# STM32MP153 register map
File version: 1.3
CPU: CM4 r0p1, little endian, no MPU, FPU, 4 interrupt priority bits
Registers are 32-bit, read-write, reset 0x0 unless marked. A register's access mark holds for its fields unless they carry their own. Offsets are from the block's base; [hi:lo] are bit positions; lines under a group give offsets from that group; {n}, {i} and the like mark numbered series; 'fields as' and 'values as' point back to an identical list.

## ETH_MAC_MMC
Base 0x5800A000
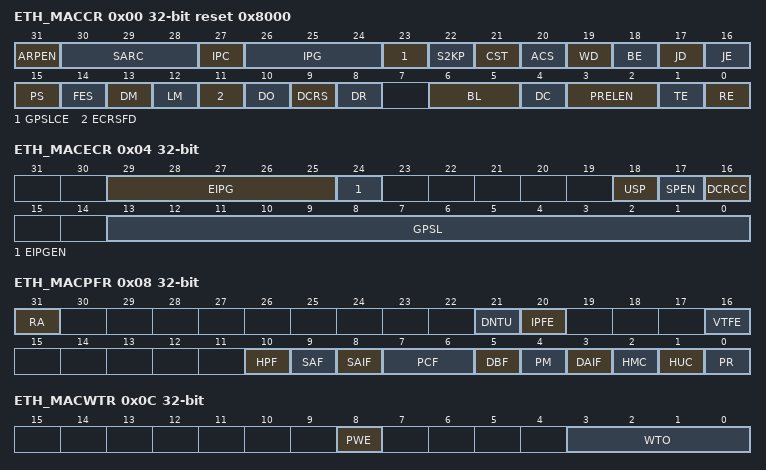
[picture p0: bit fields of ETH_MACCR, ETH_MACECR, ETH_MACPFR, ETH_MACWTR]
0x00 ETH_MACCR reset 0x8000 — The MAC Configuration Register establishes the operating mode of the MAC.
  [31] ARPEN, [30:28] SARC, [27] IPC, [26:24] IPG, [23] GPSLCE, [22] S2KP, [21] CST, [20] ACS, [19] WD, [18] BE, [17] JD, [16] JE, [15] PS, [14] FES, [13] DM, [12] LM, [11] ECRSFD, [10] DO, [9] DCRS, [8] DR, [6:5] BL, [4] DC, [3:2] PRELEN, [1] TE, [0] RE
0x04 ETH_MACECR — The MAC Extended Configuration Register establishes the operating mode of the MAC.
  [29:25] EIPG, [24] EIPGEN, [18] USP, [17] SPEN, [16] DCRCC, [13:0] GPSL
0x08 ETH_MACPFR — The MAC Packet Filter register contains the filter controls for receiving packets. Some of the controls from this register go to the address check block of the MAC which performs the first level of address filtering. The second level of filtering is performed on the incoming packet based on other controls such as Pass Bad Packets and Pass Control Packets.
  [31] RA, [21] DNTU, [20] IPFE, [16] VTFE, [10] HPF, [9] SAF, [8] SAIF, [7:6] PCF, [5] DBF, [4] PM, [3] DAIF, [2] HMC, [1] HUC, [0] PR
0x0C ETH_MACWTR — The Watchdog Timeout register controls the watchdog timeout for received packets.
  [8] PWE, [3:0] WTO
0x10 ETH_MACHT0R — The Hash Table Register 0 contains the first 32 bits of the Hash table (64 bits). For Hash filtering, the content of the destination address in the incoming packet is passed through the CRC logic and the upper six bits of the CRC register are used to index the content of the Hash table. The most significant bits determines the register to be used (Hash Table Register 0 or 1). The Hash value of the destination address is calculated in the following way: Calculate the 32-bit CRC for the DA (See IEEE 802.3, Section 3.2.8 for the steps to calculate CRC32). Perform bitwise reversal for the value obtained in Step 1. Take the upper 7 or 8 bits from the value obtained in Step 2. If the corresponding bit value of the register is 1, the packet is accepted. Otherwise, it is rejected. If the PM bit is set in ETH_MACPFR, all multicast packets are accepted regardless of the multicast Hash values. If the Hash Table register is configured to be double-synchronized to the GMII clock domain, the synchronization is triggered only when Bits[31:24] (in little-endian mode) or Bits[7:0] (in big-endian mode) of the Hash Table Register X registers are written.
  [31:0] HT31T0
0x14 ETH_MACHT1R — The Hash Table Register 1contains the last 32 bits of the Hash table (64 bits). For Hash filtering, the content of the destination address in the incoming packet is passed through the CRC logic and the upper six bits of the CRC register are used to index the content of the Hash table. The most significant bits determines the register to be used (Hash Table Register 0 or 1). The Hash value of the destination address is calculated in the following way: Calculate the 32-bit CRC for the DA (See IEEE 802.3, Section 3.2.8 for the steps to calculate CRC32). Perform bitwise reversal for the value obtained in Step 1. Take the upper 7 or 8 bits from the value obtained in Step 2. If the corresponding bit value of the register is 1, the packet is accepted. Otherwise, it is rejected. If the PM bit is set in ETH_MACPFR, all multicast packets are accepted regardless of the multicast Hash values. If the Hash Table register is configured to be double-synchronized to the GMII clock domain, the synchronization is triggered only when Bits[31:24] (in little-endian mode) or Bits[7:0] (in big-endian mode) of the Hash Table Register X registers are written.
  [31:0] HT63T32
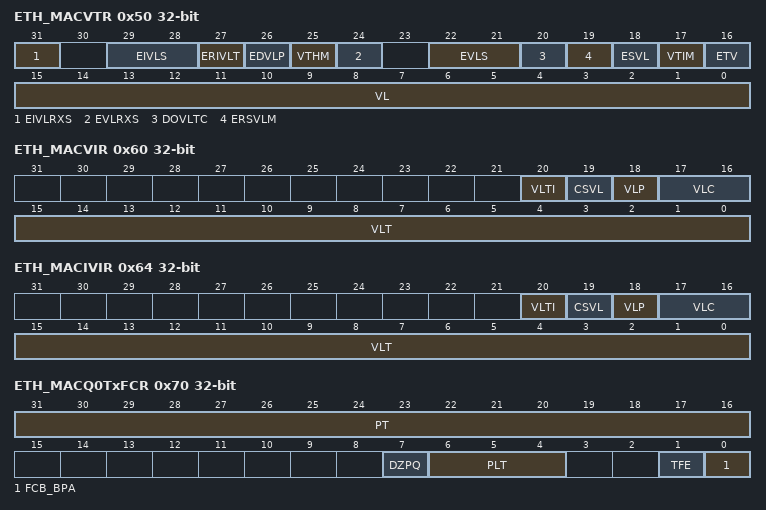
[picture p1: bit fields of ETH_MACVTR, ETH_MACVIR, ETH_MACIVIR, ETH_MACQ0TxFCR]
0x50 ETH_MACVTR — The VLAN Tag register identifies the IEEE 802.1Q VLAN type packets.
  [31] EIVLRXS, [29:28] EIVLS, [27] ERIVLT, [26] EDVLP, [25] VTHM, [24] EVLRXS, [22:21] EVLS, [20] DOVLTC, [19] ERSVLM, [18] ESVL, [17] VTIM, [16] ETV, [15:0] VL
0x58 ETH_MACVHTR — When the ERSVLM bit of ETH_MACHT1R register is set, the 16-bit VLAN Hash Table register is used for group address filtering based on the VLAN tag. For Hash filtering, the content of the 16-bit VLAN tag or 12-bit VLAN ID (based on the ETV bit of ETH_MACVTR register) in the incoming packet is passed through the CRC logic. The upper four bits of the calculated CRC are used to index the contents of the VLAN Hash table. For example, a Hash value of 1000 selects Bit 8 of the VLAN Hash table. The Hash value of the destination address is calculated in the following way: Calculate the 32-bit CRC for the VLAN tag or ID (For steps to calculate CRC32, see Section 3.2.8 of IEEE 802.3). Perform bitwise reversal for the value obtained in step 1. Take the upper four bits from the value obtained in step 2. If the VLAN Hash Table register is configured to be double-synchronized to the GMII clock domain, the synchronization is triggered only when Bits[15:8] (in little-endian mode) or Bits[7:0] (in big-endian mode) of this register are written.
  [15:0] VLHT
0x60 ETH_MACVIR — The VLAN Tag Inclusion or Replacement register contains the VLAN tag for insertion or replacement in the Transmit packets. It also contains the VLAN tag insertion controls.
  [20] VLTI, [19] CSVL, [18] VLP, [17:16] VLC, [15:0] VLT
0x64 ETH_MACIVIR — The Inner VLAN Tag Inclusion or Replacement register contains the inner VLAN tag to be inserted or replaced in the Transmit packet. It also contains the inner VLAN tag insertion controls.
  [20] VLTI, [19] CSVL, [18] VLP, [17:16] VLC, [15:0] VLT
0x70 ETH_MACQ0TxFCR — The Flow Control register controls the generation and reception of the Control (Pause Command) packets by the Flow control module of the MAC. A Write to a register with the Busy bit set to 1 triggers the Flow Control block to generate a Pause packet. The fields of the control packet are selected as specified in the 802.3x specification, and the Pause Time value from this register is used in the Pause Time field of the control packet. The Busy bit remains set until the control packet is transferred onto the cable. The application must make sure that the Busy bit is cleared before writing to the register.
  [31:16] PT, [7] DZPQ, [6:4] PLT, [1] TFE, [0] FCB_BPA
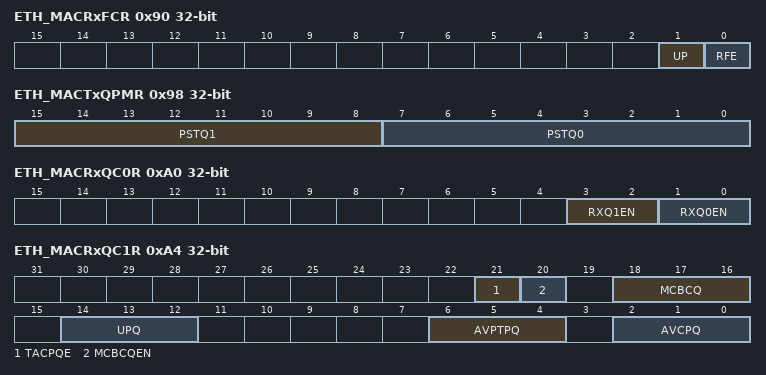
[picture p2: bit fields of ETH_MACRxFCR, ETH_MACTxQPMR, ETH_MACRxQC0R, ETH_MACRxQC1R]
0x90 ETH_MACRxFCR — The Receive Flow Control register controls the pausing of MAC Transmit based on the received Pause packet.
  [1] UP, [0] RFE
0x98 ETH_MACTxQPMR ro — The transmit queue priority mapping 0 register contains the priority values assigned to Tx queue 0 and tx queue 1.
  [15:8] PSTQ1, [7:0] PSTQ0
0xA0 ETH_MACRxQC0R — The Receive Queue Control 0 register controls the queue management in the MAC Receiver.
  [3:2] RXQ1EN, [1:0] RXQ0EN
0xA4 ETH_MACRxQC1R — The Receive Queue Control 1 register controls queue 1 management in the MAC receiver.
  [21] TACPQE, [20] MCBCQEN, [18:16] MCBCQ, [14:12] UPQ, [6:4] AVPTPQ, [2:0] AVCPQ
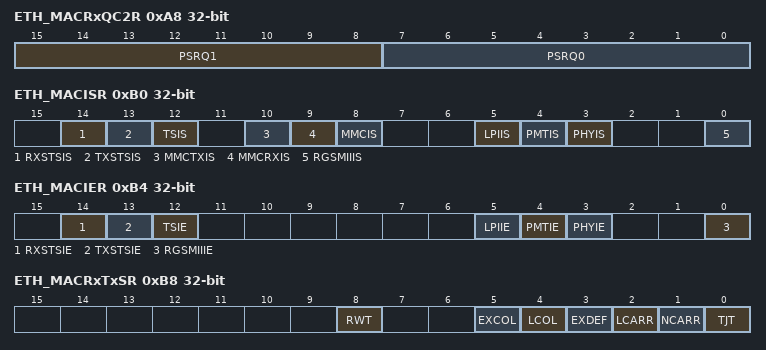
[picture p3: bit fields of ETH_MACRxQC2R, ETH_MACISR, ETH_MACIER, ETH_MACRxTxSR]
0xA8 ETH_MACRxQC2R — This register controls the routing of tagged packets based on the USP (user priority) field of the received packets to the Rx queue 0 and 1.
  [15:8] PSRQ1, [7:0] PSRQ0
0xB0 ETH_MACISR ro — The Interrupt Status register contains the status of interrupts.
  [14] RXSTSIS, [13] TXSTSIS, [12] TSIS, [10] MMCTXIS, [9] MMCRXIS, [8] MMCIS, [5] LPIIS, [4] PMTIS, [3] PHYIS, [0] RGSMIIIS
0xB4 ETH_MACIER — The Interrupt Enable register contains the masks for generating the interrupts.
  [14] RXSTSIE, [13] TXSTSIE, [12] TSIE, [5] LPIIE, [4] PMTIE, [3] PHYIE, [0] RGSMIIIE
0xB8 ETH_MACRxTxSR ro — The Receive Transmit Status register contains the Receive and Transmit Error status.
  [8] RWT, [5] EXCOL, [4] LCOL, [3] EXDEF, [2] LCARR, [1] NCARR, [0] TJT
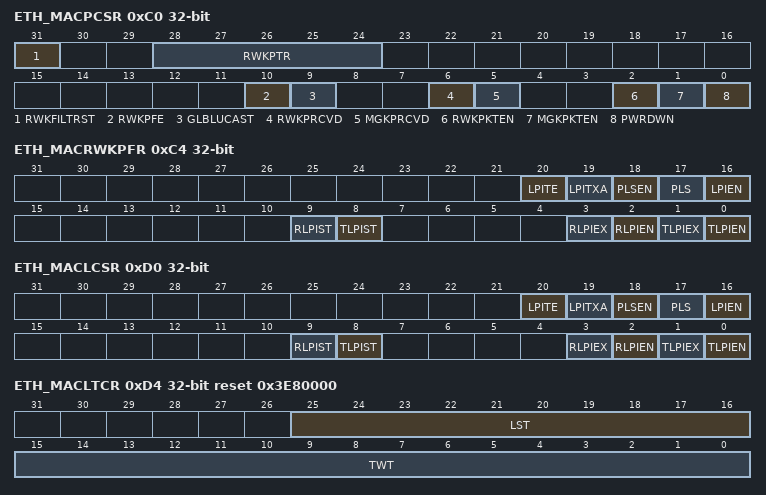
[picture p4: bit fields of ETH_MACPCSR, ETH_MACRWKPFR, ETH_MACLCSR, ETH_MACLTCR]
0xC0 ETH_MACPCSR — The PMT Control and Status Register is present only when you select the PMT module in coreConsultant.
  [31] RWKFILTRST, [28:24] RWKPTR ro, [10] RWKPFE, [9] GLBLUCAST, [6] RWKPRCVD ro, [5] MGKPRCVD ro, [2] RWKPKTEN, [1] MGKPKTEN, [0] PWRDWN
0xC4 ETH_MACRWKPFR — The LPI Control and Status Register controls the LPI functions and provides the LPI interrupt status. The status bits are cleared when this register is read.
  [20] LPITE, [19] LPITXA, [18] PLSEN, [17] PLS, [16] LPIEN, [9] RLPIST ro, [8] TLPIST ro, [3] RLPIEX ro, [2] RLPIEN ro, [1] TLPIEX ro, [0] TLPIEN ro
0xD0 ETH_MACLCSR — The LPI Control and Status Register controls the LPI functions and provides the LPI interrupt status. The status bits are cleared when this register is read.
  fields as ETH_MACRWKPFR
0xD4 ETH_MACLTCR reset 0x3E80000 — The LPI Timers Control register controls the timeout values in the LPI states. It specifies the time for which the MAC transmits the LPI pattern and also the time for which the MAC waits before resuming the normal transmission.
  [25:16] LST, [15:0] TWT
0xD8 ETH_MACLETR — The LPI Entry Timer Register is used to store the LPI Idle Timer Value in Micro-Seconds.
  [19:3] LPIET
0xDC ETH_MAC1USTCR — This register controls the generation of the Reference time (1-microsecond tick) for all the LPI timers. This timer has to be programmed by the software initially.
  [11:0] TIC_1US_CNTR
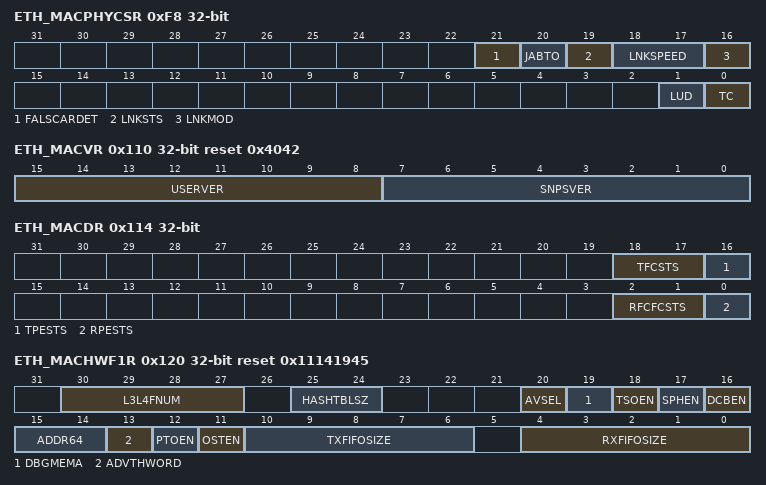
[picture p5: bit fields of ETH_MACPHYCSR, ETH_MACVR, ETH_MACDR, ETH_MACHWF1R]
0xF8 ETH_MACPHYCSR — The PHY Interface Control and Status register indicates the status signals received by the, RGMII interface from the PHY.
  [21] FALSCARDET ro, [20] JABTO ro, [19] LNKSTS ro, [18:17] LNKSPEED ro, [16] LNKMOD ro, [1] LUD, [0] TC
0x110 ETH_MACVR ro reset 0x4042 — The version register identifies the version of the Ethernet peripheral.
  [15:8] USERVER, [7:0] SNPSVER
0x114 ETH_MACDR ro — The Debug register provides the debug status of various MAC blocks.
  [18:17] TFCSTS, [16] TPESTS, [2:1] RFCFCSTS, [0] RPESTS
0x120 ETH_MACHWF1R ro reset 0x11141945 — This register indicates the presence of second set of the optional features or functions of the Ethernet peripheral. The software driver can use this register to dynamically enable or disable the programs related to the optional blocks.
  [30:27] L3L4FNUM, [25:24] HASHTBLSZ, [20] AVSEL, [19] DBGMEMA, [18] TSOEN, [17] SPHEN, [16] DCBEN, [15:14] ADDR64, [13] ADVTHWORD, [12] PTOEN, [11] OSTEN, [10:6] TXFIFOSIZE, [4:0] RXFIFOSIZE
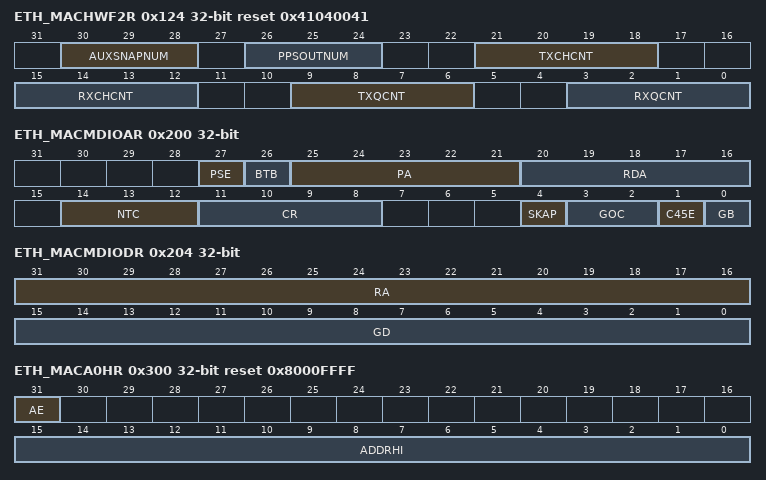
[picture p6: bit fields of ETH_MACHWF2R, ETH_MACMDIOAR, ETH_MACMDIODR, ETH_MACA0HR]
0x124 ETH_MACHWF2R ro reset 0x41040041 — This register indicates the presence of third set of the optional features or functions of the Ethernet peripheral. The software driver can use this register to dynamically enable or disable the programs related to the optional blocks.
  [30:28] AUXSNAPNUM, [26:24] PPSOUTNUM, [21:18] TXCHCNT, [15:12] RXCHCNT, [9:6] TXQCNT, [3:0] RXQCNT
0x200 ETH_MACMDIOAR — The MDIO Address register controls the management cycles to external PHY through a management interface.
  [27] PSE, [26] BTB, [25:21] PA, [20:16] RDA, [14:12] NTC, [11:8] CR, [4] SKAP, [3:2] GOC, [1] C45E, [0] GB
0x204 ETH_MACMDIODR — The MDIO Data register stores the Write data to be written to the PHY register located at the address specified in ETH_MACMDIOAR. This register also stores the Read data from the PHY register located at the address specified by MDIO Address register.
  [31:16] RA, [15:0] GD
0x300 ETH_MACA0HR reset 0x8000FFFF — The MAC Address0 High register holds the upper 16 bits of the first 6-byte MAC address of the station. The first DA byte that is received on the GMII interface corresponds to the LS byte (Bits [7:0]) of the MAC Address Low register. For example, if 0x112233445566 is received (0x11 in lane 0 of the first column) on the GMII as the destination address, then the MacAddress0 Register [47:0] is compared with 0x665544332211. If the MAC address registers are configured to be double-synchronized to the GMII clock domains, then the synchronization is triggered only when Bits[31:24] (in little-endian mode) or Bits[7:0] (in big-endian mode) of the MAC Address0 Low Register are written. For proper synchronization updates, the consecutive writes to this Address Low Register should be performed after at least four clock cycles in the destination clock domain.
  [31] AE ro, [15:0] ADDRHI
{0x304+8i} ETH_MACA{i}LR reset 0xFFFFFFFF (i=0..3) — The MAC Address x Low register holds the lower 32 bits of the 6-byte first MAC address of the station.
  [31:0] ADDRLO
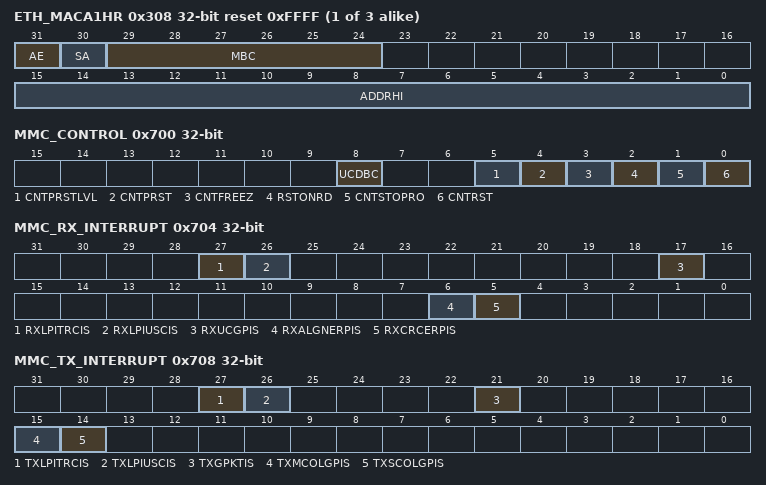
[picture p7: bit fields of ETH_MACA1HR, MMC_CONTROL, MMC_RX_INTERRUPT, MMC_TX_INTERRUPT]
{0x300+8i} ETH_MACA{i}HR reset 0xFFFF (i=1..3) — The MAC Address x High register holds the upper 16 bits of the second 6-byte MAC address of the station.
  [31] AE, [30] SA, [29:24] MBC, [15:0] ADDRHI
0x700 MMC_CONTROL — This register configures the MMC operating mode.
  [8] UCDBC, [5] CNTPRSTLVL, [4] CNTPRST, [3] CNTFREEZ, [2] RSTONRD, [1] CNTSTOPRO, [0] CNTRST
0x704 MMC_RX_INTERRUPT ro — This register maintains the interrupts generated from all Receive statistics counters. The MMC Receive Interrupt register maintains the interrupts that are generated when the following occur: Receive statistic counters reach half of their maximum values (0x8000_0000 for 32 bit counter and 0x8000 for 16 bit counter). Receive statistic counters cross their maximum values (0xFFFF_FFFF for 32 bit counter and 0xFFFF for 16 bit counter). When the Counter Stop Rollover is set, interrupts are set but the counter remains at all-ones. The MMC Receive Interrupt register is a 32 bit register. An interrupt bit is cleared when the respective MMC counter that caused the interrupt is read. The least significant byte lane (Bits[7:0]) of the respective counter must be read to clear the interrupt bit.
  [27] RXLPITRCIS, [26] RXLPIUSCIS, [17] RXUCGPIS, [6] RXALGNERPIS, [5] RXCRCERPIS
0x708 MMC_TX_INTERRUPT ro — This register maintains the interrupts generated from all Transmit statistics counters. The MMC Transmit Interrupt register maintains the interrupts generated when transmit statistic counters reach half their maximum values (0x8000_0000 for 32 bit counter and 0x8000 for 16 bit counter), and when they cross their maximum values (0xFFFF_FFFF for 32-bit counter and 0xFFFF for 16-bit counter). When Counter Stop Rollover is set, the interrupts are set but the counter remains at all-ones. The MMC Transmit Interrupt register is a 32 bit register. An interrupt bit is cleared when the respective MMC counter that caused the interrupt is read. The least significant byte lane (Bits[7:0]) of the respective counter must be read to clear the interrupt bit.
  [27] TXLPITRCIS, [26] TXLPIUSCIS, [21] TXGPKTIS, [15] TXMCOLGPIS, [14] TXSCOLGPIS
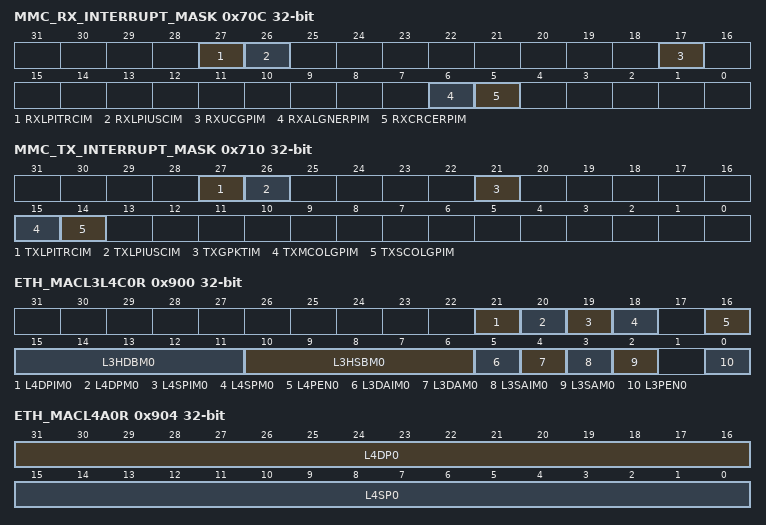
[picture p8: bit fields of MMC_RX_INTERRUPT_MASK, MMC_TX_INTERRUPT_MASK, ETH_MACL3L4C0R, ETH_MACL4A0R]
0x70C MMC_RX_INTERRUPT_MASK — The MMC Receive Interrupt Mask register maintains the masks for the interrupts generated when receive statistic counters reach half of their maximum value or the maximum values.
  [27] RXLPITRCIM ro, [26] RXLPIUSCIM, [17] RXUCGPIM, [6] RXALGNERPIM, [5] RXCRCERPIM
0x710 MMC_TX_INTERRUPT_MASK — This register maintains the masks for interrupts generated from all Transmit statistics counters. The MMC Transmit Interrupt Mask register maintains the masks for the interrupts generated when the transmit statistic counters reach half of their maximum value or the maximum values. This register is 32 bit wide. This register is present only when any one of the MMC Transmit Counters is selected during core configuration.
  [27] TXLPITRCIM ro, [26] TXLPIUSCIM, [21] TXGPKTIM, [15] TXMCOLGPIM, [14] TXSCOLGPIM
0x74C TX_SINGLE_COLLISION_GOOD_PACKETS ro — This register provides the number of successfully transmitted packets by Ethernet peripheral after a single collision in the half-duplex mode.
  [31:0] TXSNGLCOLG
0x750 TX_MULTIPLE_COLLISION_GOOD_PACKETS ro — This register provides the number of successfully transmitted packets by Ethernet peripheral after multiple collisions in the half-duplex mode.
  [31:0] TXMULTCOLG
0x768 TX_PACKET_COUNT_GOOD ro — This register provides the number of good packets transmitted by Ethernet peripheral.
  [31:0] TXPKTG
0x794 RX_CRC_ERROR_PACKETS ro — This register provides the number of packets received by Ethernet peripheral with CRC error.
  [31:0] RXCRCERR
0x798 RX_ALIGNMENT_ERROR_PACKETS ro — This register provides the number of packets received by Ethernet peripheral with alignment (dribble) error. It is valid only in 10/100 mode.
  [31:0] RXALGNERR
0x7C4 RX_UNICAST_PACKETS_GOOD ro — This register provides the number of good unicast packets received by Ethernet peripheral.
  [31:0] RXUCASTG
0x7EC TX_LPI_USEC_CNTR ro — This register provides the number of microseconds Tx LPI is asserted by Ethernet peripheral.
  [31:0] TXLPIUSC
0x7F0 TX_LPI_TRAN_CNTR ro — This register provides the number of times Ethernet peripheral has entered Tx LPI.
  [31:0] TXLPITRC
0x7F4 RX_LPI_USEC_CNTR ro — This register provides the number of microseconds Rx LPI is sampled by Ethernet peripheral.
  [31:0] RXLPIUSC
0x7F8 RX_LPI_TRAN_CNTR ro — This register provides the number of times Ethernet peripheral has entered Rx LPI.
  [31:0] RXLPITRC
0x900 ETH_MACL3L4C0R — The Layer 3 and Layer 4 Control register controls the operations of filter 0 of Layer 3 and Layer 4. This register is reserved if the Layer 3 and Layer 4 Filtering feature is not selected during core configuration.
  [21] L4DPIM0, [20] L4DPM0, [19] L4SPIM0, [18] L4SPM0, [16] L4PEN0, [15:11] L3HDBM0, [10:6] L3HSBM0, [5] L3DAIM0, [4] L3DAM0, [3] L3SAIM0, [2] L3SAM0, [0] L3PEN0
0x904 ETH_MACL4A0R — Layer4 address filter 0 register
  [31:16] L4DP0, [15:0] L4SP0
0x910 ETH_MACL3A00R — For IPv4 packets, the Layer 3 Address 0 Register 0 register contains the 32-bit IP Source Address field. For IPv6 packets, it contains Bits[31:0] of the 128-bit IP Source Address or Destination Address field.
  [31:0] L3A00
0x914 ETH_MACL3A10R — For IPv4 packets, the Layer 3 Address 1 Register 0 register contains the 32-bit IP Destination Address field. For IPv6 packets, it contains Bits[63:32] of the 128-bit IP Source Address or Destination Address field.
  [31:0] L3A10
0x918 ETH_MACL3A20 — The Layer 3 Address 2 Register 0 register is reserved for IPv4 packets. For IPv6 packets, it contains Bits[95:64] of 128-bit IP Source Address or Destination Address field.
  [31:0] L3A20
0x91C ETH_MACL3A30 — The Layer 3 Address 3 Register 0 register is reserved for IPv4 packets. For IPv6 packets, it contains Bits[127:96] of 128-bit IP Source Address or Destination Address field.
  [31:0] L3A30
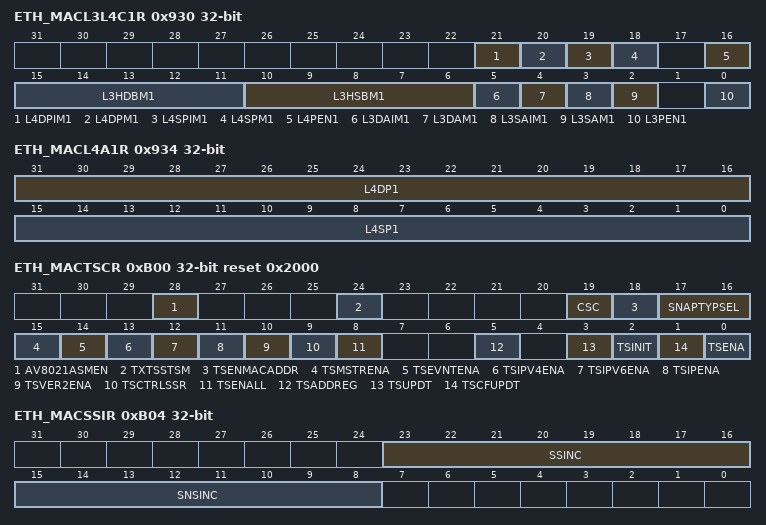
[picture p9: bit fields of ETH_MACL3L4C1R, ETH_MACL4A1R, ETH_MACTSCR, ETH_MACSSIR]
0x930 ETH_MACL3L4C1R — The Layer 3 and Layer 4 Control register controls the operations of filter 0 of Layer 3 and Layer 4.
  [21] L4DPIM1, [20] L4DPM1, [19] L4SPIM1, [18] L4SPM1, [16] L4PEN1, [15:11] L3HDBM1, [10:6] L3HSBM1, [5] L3DAIM1, [4] L3DAM1, [3] L3SAIM1, [2] L3SAM1, [0] L3PEN1
0x934 ETH_MACL4A1R — The Layer 4 Address 0 register and registers 580 through 667 are reserved (RO with default value) if Enable Layer 3 and Layer 4 Packet Filter option is not selected while configuring the core. You can configure the Layer 3 and Layer 4 Address Registers to be double-synchronized by selecting the Synchronize Layer 3 and Layer 4 Address Registers to Rx Clock Domain option while configuring the core. When you select this option, the synchronization is triggered only when Bits[31:24] (in little-endian mode) or Bits[7:0] (in big-endian mode) of the Layer 3 and Layer 4 Address Registers are written. For proper synchronization updates, you should perform consecutive writes to same Layer 3 and Layer 4 Address Registers after at least four clock cycles delay of the destination clock.
  [31:16] L4DP1, [15:0] L4SP1
0x940 ETH_MACL3A01R — For IPv4 packets, the Layer 3 Address 0 Register 0 register contains the 32-bit IP Source Address field. For IPv6 packets, it contains Bits[31:0] of the 128-bit IP Source Address or Destination Address field.
  [31:0] L3A01
0x944 ETH_MACL3A11R — For IPv4 packets, the Layer 3 Address 1 Register 0 register contains the 32-bit IP Destination Address field. For IPv6 packets, it contains Bits[63:32] of the 128-bit IP Source Address or Destination Address field.
  [31:0] L3A11
0x948 ETH_MACL3A21R — The Layer 3 Address 2 Register 0 register is reserved for IPv4 packets. For IPv6 packets, it contains Bits[95:64] of 128-bit IP Source Address or Destination Address field.
  [31:0] L3A21
0x94C ETH_MACL3A31R — The Layer 3 Address 3 Register 0 register is reserved for IPv4 packets. For IPv6 packets, it contains Bits[127:96] of 128-bit IP Source Address or Destination Address field.
  [31:0] L3A31
0xAE0 ETH_MACARPAR — The ARP Address register contains the IPv4 Destination Address of the MAC.
  [31:0] ARPPA
0xB00 ETH_MACTSCR reset 0x2000 — This register controls the operation of the System Time generator and processing of PTP packets for timestamping in the Receiver.
  [28] AV8021ASMEN, [24] TXTSSTSM, [19] CSC ro, [18] TSENMACADDR, [17:16] SNAPTYPSEL, [15] TSMSTRENA, [14] TSEVNTENA, [13] TSIPV4ENA, [12] TSIPV6ENA, [11] TSIPENA, [10] TSVER2ENA, [9] TSCTRLSSR, [8] TSENALL, [5] TSADDREG, [3] TSUPDT, [2] TSINIT, [1] TSCFUPDT, [0] TSENA
0xB04 ETH_MACSSIR — The Sub-second Increment register is present only when the IEEE 1588 timestamp feature is selected without an external timestamp input. In Coarse Update mode [Bit 1 in ETH_MACTSCR register, the value in this register is added to the system time every clock cycle of HCLK. In Fine Update mode, the value in this register is added to the system time whenever the Accumulator gets an overflow.
  [23:16] SSINC, [15:8] SNSINC
0xB08 ETH_MACSTSR ro — The System Time Seconds register, along with System Time Nanoseconds register, indicates the current value of the system time maintained by the MAC. Though it is updated on a continuous basis, there is some delay from the actual time because of clock domain transfer latencies (from HCLK to CSR clock). This register is present only when the IEEE 1588 Timestamp feature is selected without external timestamp input.
  [31:0] TSS
0xB0C ETH_MACSTNR ro — The System Time Nanoseconds register, along with System Time Seconds register, indicates the current value of the system time maintained by the MAC. This register is present only when the IEEE 1588 Timestamp feature is selected without external timestamp input.
  [30:0] TSSS
0xB10 ETH_MACSTSUR — The System Time Seconds Update register, along with the System Time Nanoseconds Update register, initializes or updates the system time maintained by the MAC. You must write both registers before setting the TSINIT or TSUPDT bits in ETH_MACTSCR register. This register is present only when the IEEE 1588 Timestamp feature is selected without external timestamp input.
  [31:0] TSS
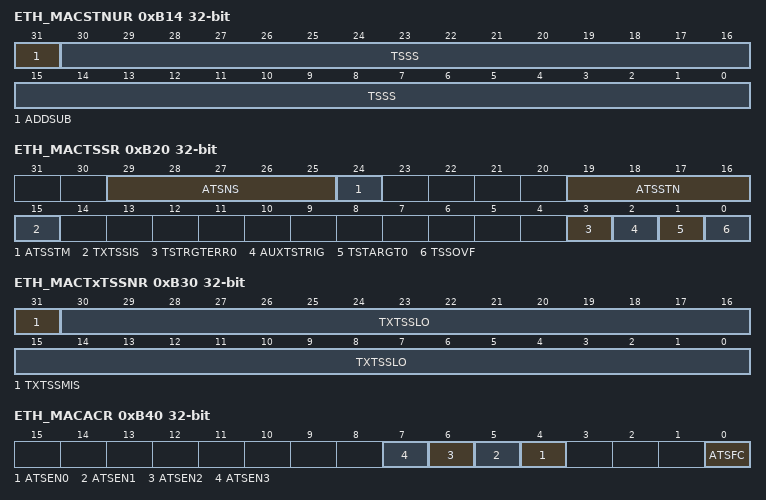
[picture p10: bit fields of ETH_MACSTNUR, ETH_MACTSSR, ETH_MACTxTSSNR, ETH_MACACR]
0xB14 ETH_MACSTNUR — This register is present only when the IEEE 1588 timestamp feature is selected without external timestamp input.
  [31] ADDSUB, [30:0] TSSS
0xB18 ETH_MACTSAR — The Timestamp Addend register is present only when the IEEE 1588 Timestamp feature is selected without external timestamp input. This register value is used only when the system time is configured for Fine Update mode (TSCFUPDT bit in the ETH_MACTSCR register). The content of this register is added to a 32-bit accumulator in every clock cycle (of HCLK) and the system time is updated whenever the accumulator overflows.
  [31:0] TSAR
0xB20 ETH_MACTSSR ro — The Timestamp Status register is present only when the IEEE 1588 Timestamp feature is selected. All bits except Bits[27:25] gets cleared when the application reads this register.
  [29:25] ATSNS, [24] ATSSTM, [19:16] ATSSTN, [15] TXTSSIS, [3] TSTRGTERR0, [2] AUXTSTRIG, [1] TSTARGT0, [0] TSSOVF
0xB30 ETH_MACTxTSSNR ro — This register contains the nanosecond part of timestamp captured for Transmit packets when Tx status is disabled.
  [31] TXTSSMIS, [30:0] TXTSSLO
0xB34 ETH_MACTxTSSSR ro — The register contains the higher 32 bits of the timestamp (in seconds) captured when a PTP packet is transmitted.
  [31:0] TXTSSHI
0xB40 ETH_MACACR — The Auxiliary Timestamp Control register controls the Auxiliary Timestamp snapshot.
  [n+4] ATSEN{n} (n=0..3), [0] ATSFC
0xB48 ETH_MACATSNR ro — The Auxiliary Timestamp Nanoseconds register, along with ETH_MACATSSR, gives the 64-bit timestamp stored as auxiliary snapshot. These two registers form the read port of a 64-bit wide FIFO with a depth of 4 words. You can store multiple snapshots in this FIFO. Bits[29:25] in ETH_MACTSSR indicate the fill-level of the FIFO. The top of the FIFO is removed only when the last byte of MAC Register 91 (Auxiliary Timestamp - Seconds Register) is read. In the little-endian mode, this means when Bits[31:24] are read and in big-endian mode, Bits[7:0] are read.
  [30:0] AUXTSLO
0xB4C ETH_MACATSSR ro — The Auxiliary Timestamp - Seconds register contains the lower 32 bits of the Seconds field of the auxiliary timestamp register.
  [31:0] AUXTSHI
0xB50 ETH_MACTSIACR — The MAC Timestamp Ingress Asymmetry Correction register contains the Ingress Asymmetry Correction value to be used while updating correction field in PDelay_Resp PTP messages.
  [31:0] OSTIAC
0xB54 ETH_MACTSEACR — The MAC Timestamp Egress Asymmetry Correction register contains the Egress Asymmetry Correction value to be used while updating the correction field in PDelay_Req PTP messages.
  [31:0] OSTEAC
0xB58 ETH_MACTSICNR — This register contains the correction value in nanoseconds to be used with the captured timestamp value in the ingress path.
  [31:0] TSIC
0xB5C ETH_MACTSECNR — This register contains the correction value in nanoseconds to be used with the captured timestamp value in the egress path.
  [31:0] TSEC
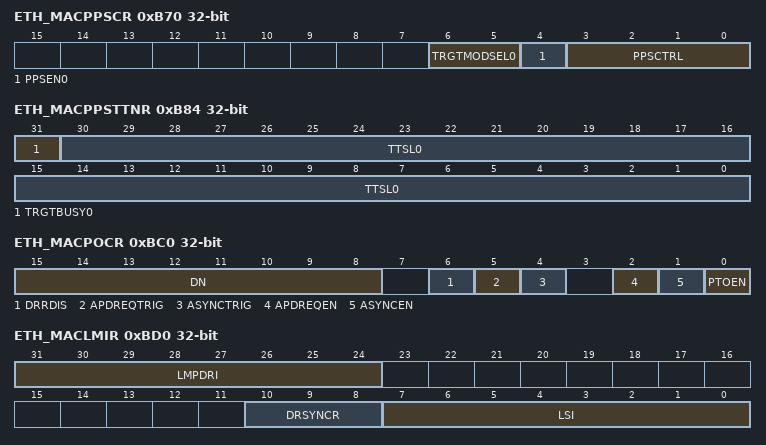
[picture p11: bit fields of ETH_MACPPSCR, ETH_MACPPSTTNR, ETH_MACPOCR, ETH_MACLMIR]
0xB70 ETH_MACPPSCR — The PPS Control register is present only when the Timestamp feature is selected and External Timestamp is not enabled. Bits[30:24] of this register are valid only when four Flexible PPS outputs are selected. Bits[22:16] are valid only when three or more Flexible PPS outputs are selected. Bits[14:8] are valid only when two or more Flexible PPS outputs are selected. Bits[6:4] are valid only when Flexible PPS feature is selected.
  [6:5] TRGTMODSEL0, [4] PPSEN0, [3:0] PPSCTRL
0xB80 ETH_MACPPSTTSR — The PPS Target Time Seconds register, along with PPS Target Time Nanoseconds register, is used to schedule an interrupt event [Bit 1 of ETH_MACTSSR] when the system time exceeds the value programmed in these registers.
  [31:0] TSTRH0
0xB84 ETH_MACPPSTTNR — The PPS Target Time Nanoseconds register is present only when more than one Flexible PPS output is selected.
  [31] TRGTBUSY0, [30:0] TTSL0
0xB88 ETH_MACPPSIR — The PPS Interval register contains the number of units of sub-second increment value between the rising edges of PPS signal output (ptp_pps_o[0]).
  [31:0] PPSINT0
0xB8C ETH_MACPPSWR — The PPS Width register contains the number of units of sub-second increment value between the rising and corresponding falling edges of PPS signal output (ptp_pps_o).
  [31:0] PPSWIDTH0
0xBC0 ETH_MACPOCR — This register controls the PTP Offload Engine operation. This register is available only when the Enable PTP Timestamp Offload feature is selected.
  [15:8] DN, [6] DRRDIS, [5] APDREQTRIG, [4] ASYNCTRIG, [2] APDREQEN, [1] ASYNCEN, [0] PTOEN
0xBC4 ETH_MACSPI0R — This register contains Bits[31:0] of the 80-bit Source Port Identity of the PTP node. This register is available only when the Enable PTP Timestamp Offload feature is selected.
  [31:0] SPI0
0xBC8 ETH_MACSPI1R — This register contains Bits[63:32] of the 80-bit Source Port Identity of the PTP node. This register is available only when the Enable PTP Timestamp Offload feature is selected.
  [31:0] SPI1
0xBCC ETH_MACSPI2R — This register contains Bits[79:64] of the 80-bit Source Port Identity of the PTP node.
  [15:0] SPI2
0xBD0 ETH_MACLMIR — This register contains the periodic intervals for automatic PTP packet generation.
  [31:24] LMPDRI, [10:8] DRSYNCR, [7:0] LSI
